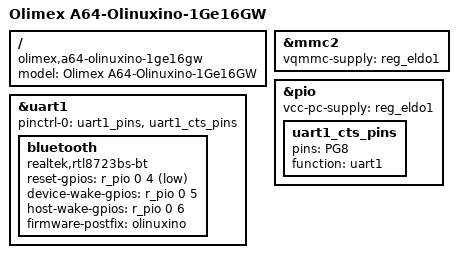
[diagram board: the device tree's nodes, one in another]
// SPDX-License-Identifier: (GPL-2.0+ OR MIT)
/*
 * Copyright (C) 2019 OLIMEX Ltd.
 *
 */

/dts-v1/;

#include "sun50i-a64-olinuxino-1Ge4GW.dts"

/ {
	model = "Olimex A64-Olinuxino-1Ge16GW";
	compatible = "olimex,a64-olinuxino-1ge16gw", "allwinner,sun50i-a64";
};

&mmc2 {
	vqmmc-supply = <&reg_eldo1>;
/*	mmc-hs200-1_8v;
	allwinner,drive-data-phase = <180>;*/
};

&pio {
	vcc-pc-supply = <&reg_eldo1>;
	uart1_cts_pins: uart1_cts_pins {
		pins = "PG8";
		function = "uart1";
	};
};

&uart1 {
        pinctrl-names = "default";
        pinctrl-0 = <&uart1_pins>, <&uart1_cts_pins>;
        status = "okay";
        bluetooth {
                compatible = "realtek,rtl8723bs-bt";
                reset-gpios = <&r_pio 0 4 GPIO_ACTIVE_LOW>; /* PL4 */
                device-wake-gpios = <&r_pio 0 5 GPIO_ACTIVE_HIGH>; /* PL5 */
                host-wake-gpios = <&r_pio 0 6 GPIO_ACTIVE_HIGH>; /* PL6 */
                firmware-postfix = "olinuxino";
        };
};
